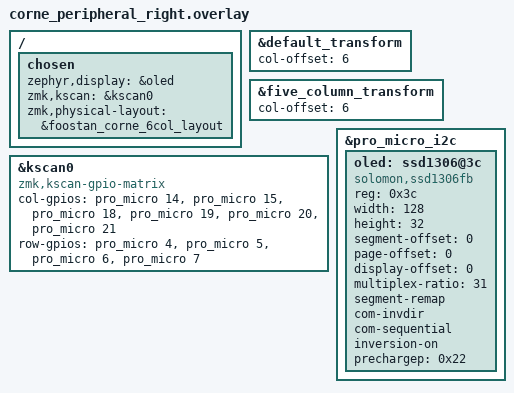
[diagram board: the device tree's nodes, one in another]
/*
 * Copyright (c) 2020 Pete Johanson
 *
 * SPDX-License-Identifier: MIT
 */

#include "corne.dtsi"

&default_transform {
    col-offset = <6>;
};

&five_column_transform {
    col-offset = <6>;
};

&kscan0 {
        compatible = "zmk,kscan-gpio-matrix";

        col-gpios
            = <&pro_micro 14 GPIO_ACTIVE_HIGH>
            , <&pro_micro 15 GPIO_ACTIVE_HIGH>
            , <&pro_micro 18 GPIO_ACTIVE_HIGH>
            , <&pro_micro 19 GPIO_ACTIVE_HIGH>
            , <&pro_micro 20 GPIO_ACTIVE_HIGH>
            , <&pro_micro 21 GPIO_ACTIVE_HIGH>
            ;

    row-gpios
        = <&pro_micro 4 (GPIO_ACTIVE_HIGH | GPIO_PULL_DOWN)>
        , <&pro_micro 5 (GPIO_ACTIVE_HIGH | GPIO_PULL_DOWN)>
        , <&pro_micro 6 (GPIO_ACTIVE_HIGH | GPIO_PULL_DOWN)>
        , <&pro_micro 7 (GPIO_ACTIVE_HIGH | GPIO_PULL_DOWN)>
        ;
};
/ {
    chosen {
        zephyr,display = &oled;
        zmk,kscan = &kscan0;
        zmk,physical-layout = &foostan_corne_6col_layout;
};
};

&pro_micro_i2c {
    status = "okay";

    oled: ssd1306@3c {
        compatible = "solomon,ssd1306fb";
        reg = <0x3c>;
        width = <128>;
        height = <32>;
        segment-offset = <0>;
        page-offset = <0>;
        display-offset = <0>;
        multiplex-ratio = <31>;
        segment-remap;
        com-invdir;
        com-sequential;
        inversion-on;
        prechargep = <0x22>;
    };
};
